AUTOSAR XML (schema 00051)
package /ComponentTypes
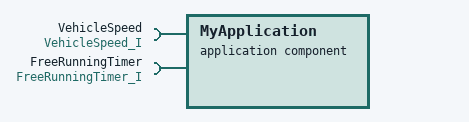
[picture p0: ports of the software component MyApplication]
  application sw component type MyApplication
    require port VehicleSpeed: nonqueued-receiver-com-spec{data-element=VehicleSpeed, init-value=65535}, required-interface=VehicleSpeed_I
    require port FreeRunningTimer: required-interface=FreeRunningTimer_I
